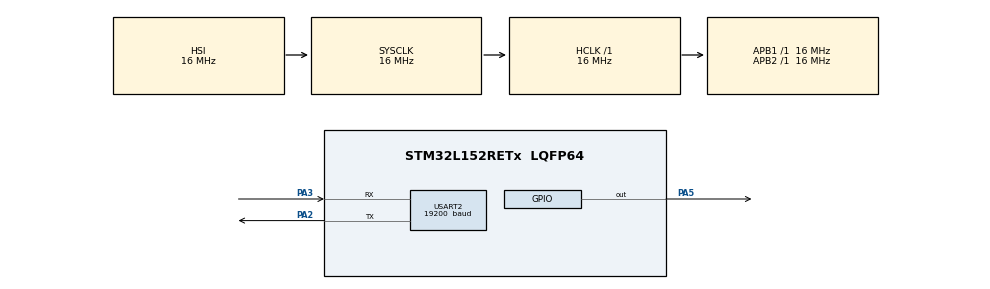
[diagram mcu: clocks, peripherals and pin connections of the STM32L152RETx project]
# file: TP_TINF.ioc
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Mcu.Family=STM32L1
RCC.MSI_VALUE=2097000
USART2.Parity=PARITY_EVEN
NVIC.USART2_IRQn=true\:0\:0\:false\:false\:true\:true\:true
USART2.BaudRate=19200 
RCC.SYSCLKSource=RCC_SYSCLKSOURCE_HSI
ProjectManager.StackSize=0x400
PA13.Signal=SYS_JTMS-SWDIO
PA3.Mode=Asynchronous
ProjectManager.TargetToolchain=TrueSTUDIO
RCC.HCLKFreq_Value=16000000
RCC.APB2TimFreq_Value=16000000
RCC.LSE_VALUE=32768
RCC.AHBFreq_Value=16000000
PA5.Signal=GPIO_Output
RCC.HSE_VALUE=24000000
board=custom
RCC.VCOOutputFreq_Value=48000000
RCC.APB2Freq_Value=16000000
PA14.Mode=Serial_Wire
PA13.Mode=Serial_Wire
Mcu.Name=STM32L152RETx
PA2.Signal=USART2_TX
RCC.SYSCLKFreq_VALUE=16000000
Mcu.Package=LQFP64
USART2.VirtualMode=VM_ASYNC
PA14.Signal=SYS_JTCK-SWCLK
ProjectManager.HeapSize=0x200
USART2.WordLength=WORDLENGTH_9B
RCC.HSI_VALUE=16000000
NVIC.PriorityGroup=NVIC_PRIORITYGROUP_4
RCC.APB1TimFreq_Value=16000000
PA2.Mode=Asynchronous
RCC.APB1Freq_Value=16000000
PA3.Signal=USART2_RX

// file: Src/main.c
/* USER CODE BEGIN Header */
/**
  ******************************************************************************
  * @file           : main.c
  * @brief          : Main program body
  ******************************************************************************
  * @attention
  *
  * <h2><center>&copy; Copyright (c) 2020 STMicroelectronics.
  * All rights reserved.</center></h2>
  *
  * This software component is licensed by ST under BSD 3-Clause license,
  * the "License"; You may not use this file except in compliance with the
  * License. You may obtain a copy of the License at:
  *                        opensource.org/licenses/BSD-3-Clause
  *
  ******************************************************************************
  */
/* USER CODE END Header */

#include "main.h"
#include "usart.h"
#include "gpio.h"
#include "MBMESN_errorstatus.h"

/* USER CODE BEGIN PV */
//volatile int a=0;

/* USER CODE END PV */

void SystemClock_Config(void);

int main(void)
{
  /* USER CODE BEGIN 1 */
	uint8_t pData[20];
	uint32_t  lengthOfData=16;
	uint32_t  totalBytesRead=0;
	uint16_t lengthOfPDU=0,lengthOfResponseFrame=0;
	uint8_t  modbusPDU[20];
	uint8_t responseFrame[30];
  /* USER CODE END 1 */

  /* MCU Configuration--------------------------------------------------------*/

  /* Reset of all peripherals, Initializes the Flash interface and the Systick. */
  HAL_Init();

  /* Configure the system clock */
  SystemClock_Config();

  /* Initialize all configured peripherals */
  MX_GPIO_Init();
  MX_USART2_UART_Init();

  /* Infinite loop */
  while (1)
  {
	  totalBytesRead=0;
	  MBMESN_serialCommRead(pData,lengthOfData,&totalBytesRead);

		 if( HandleMBRequest(pData, (uint16_t)totalBytesRead,modbusPDU ,&lengthOfPDU) != MBMESN_SLAVE_DEVICE_ERROR){

			  BuildMBResponse(modbusPDU,lengthOfPDU, responseFrame, &lengthOfResponseFrame);

			  MBMESN_serialCommWrite(responseFrame,lengthOfResponseFrame);
		 }

  }
}

void SystemClock_Config(void)
{
  RCC_OscInitTypeDef RCC_OscInitStruct = {0};
  RCC_ClkInitTypeDef RCC_ClkInitStruct = {0};

  /** Configure the main internal regulator output voltage
  */
  __HAL_PWR_VOLTAGESCALING_CONFIG(PWR_REGULATOR_VOLTAGE_SCALE1);
  /** Initializes the CPU, AHB and APB busses clocks
  */
  RCC_OscInitStruct.OscillatorType = RCC_OSCILLATORTYPE_HSI;
  RCC_OscInitStruct.HSIState = RCC_HSI_ON;
  RCC_OscInitStruct.HSICalibrationValue = RCC_HSICALIBRATION_DEFAULT;
  RCC_OscInitStruct.PLL.PLLState = RCC_PLL_NONE;
  if (HAL_RCC_OscConfig(&RCC_OscInitStruct) != HAL_OK)
  {
    Error_Handler();
  }
  /** Initializes the CPU, AHB and APB busses clocks
  */
  RCC_ClkInitStruct.ClockType = RCC_CLOCKTYPE_HCLK|RCC_CLOCKTYPE_SYSCLK
                              |RCC_CLOCKTYPE_PCLK1|RCC_CLOCKTYPE_PCLK2;
  RCC_ClkInitStruct.SYSCLKSource = RCC_SYSCLKSOURCE_HSI;
  RCC_ClkInitStruct.AHBCLKDivider = RCC_SYSCLK_DIV1;
  RCC_ClkInitStruct.APB1CLKDivider = RCC_HCLK_DIV1;
  RCC_ClkInitStruct.APB2CLKDivider = RCC_HCLK_DIV1;

  if (HAL_RCC_ClockConfig(&RCC_ClkInitStruct, FLASH_LATENCY_0) != HAL_OK)
  {
    Error_Handler();
  }
}

void Error_Handler(void)
{
}

/************************ (C) COPYRIGHT STMicroelectronics *****END OF FILE****/
